AUTOSAR XML (schema 00044)
package /ComponentTypes
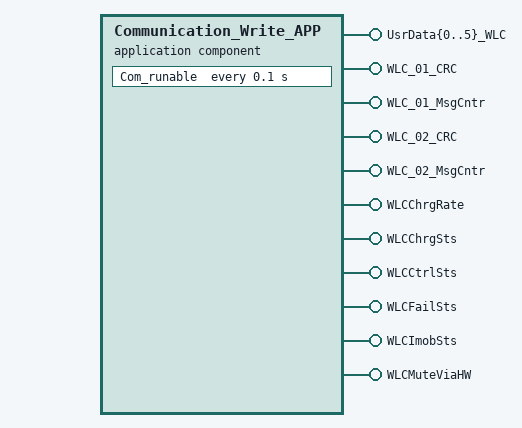
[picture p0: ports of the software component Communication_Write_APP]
  application sw component type Communication_Write_APP
    16 x provide port:
      UsrData{0..5}_WLC: nonqueued-sender-com-spec=UsrData{0..5}_WLC, provided-interface=UsrData{0..5}_WLC
      WLC_01_CRC: nonqueued-sender-com-spec=WLC_01_CRC, provided-interface=WLC_01_CRC
      WLC_01_MsgCntr: nonqueued-sender-com-spec=WLC_01_MsgCntr, provided-interface=WLC_01_MsgCntr
      WLC_02_CRC: nonqueued-sender-com-spec=WLC_02_CRC, provided-interface=WLC_02_CRC
      WLC_02_MsgCntr: nonqueued-sender-com-spec=WLC_02_MsgCntr, provided-interface=WLC_02_MsgCntr
      WLCChrgRate: nonqueued-sender-com-spec=WLCChrgRate, provided-interface=WLCChrgRate
      WLCChrgSts: nonqueued-sender-com-spec=WLCChrgSts, provided-interface=WLCChrgSts
      WLCCtrlSts: nonqueued-sender-com-spec=WLCCtrlSts, provided-interface=WLCCtrlSts
      WLCFailSts: nonqueued-sender-com-spec=WLCFailSts, provided-interface=WLCFailSts
      WLCImobSts: nonqueued-sender-com-spec=WLCImobSts, provided-interface=WLCImobSts
      WLCMuteViaHW: nonqueued-sender-com-spec=WLCMuteViaHW, provided-interface=WLCMuteViaHW
    behavior Communication_Write_APP_InternalBehavior
      timing event TMT_Com_runable: start-on-event=Com_runable, period=0.1
      runnable Com_runable
  swc implementation Communication_Write_APP_Implementation: behavior=Communication_Write_APP_InternalBehavior
